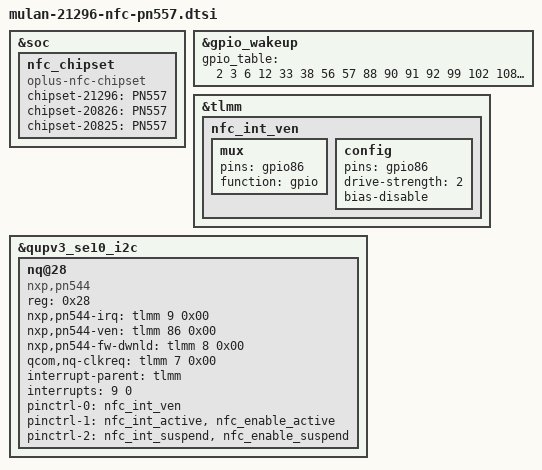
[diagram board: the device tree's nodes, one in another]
/**********************************************************************************
* Copyright (c)  2008-2020  Guangdong oplus Mobile Comm Corp., Ltd
* VENDOR_EDIT
* Description: oplus pn557 nfc dtsi
*
* Version: 1.0
* Date: 2020-09-16
* Author: Weiwei.Deng
*
* ------------------------------ Revision History: --------------------------------
* <version>           <date>                <author>                            <desc>
* Revision 1.0       2020-11-16            wenjie.liu           Created for Beta pn557 nfc dtsi
***********************************************************************************/
&soc {
	//add for nfc_chipset
	nfc_chipset {
        compatible = "oplus-nfc-chipset";
	chipset-21296 = "PN557";
        chipset-20826 = "PN557";
        chipset-20825 = "PN557";
	};
};

//add for disable wake-up function of NC-GPIO
&gpio_wakeup {
    gpio_table = <2 3 6 12 33 38 56 57 88 90 91 92 99 102 108 113 114 115 116
                  48 51 59 84 85 107 117 118 152 153 154 155>;
};

&tlmm {
    nfc_int_ven: nfc_int_ven {
	mux {
		pins = "gpio86";
		function = "gpio";
	};

	config {
		pins = "gpio86";
		drive-strength = <2>; /* 2 MA */
		bias-disable;
	};
    };
};


&qupv3_se10_i2c {
    //add for NXP PN557 NFC GPIO
	status = "ok";
	//qcom,clk-freq-out = <1000000>;
	#address-cells = <1>;
	#size-cells = <0>;
	nq@28 {
		compatible = "nxp,pn544";
		reg = <0x28>;
		nxp,pn544-irq = <&tlmm 9 0x00>;
		nxp,pn544-ven = <&tlmm 86 0x00>;
		nxp,pn544-fw-dwnld = <&tlmm 8 0x00>;
		qcom,nq-clkreq = <&tlmm 7 0x00>;
		interrupt-parent = <&tlmm>;
		interrupts = <9 0>;
		interrupt-names = "nfc_irq";
		pinctrl-names = "default","nfc_active", "nfc_suspend";
		pinctrl-0 = <&nfc_int_ven>;
		pinctrl-1 = <&nfc_int_active &nfc_enable_active>;
		pinctrl-2 = <&nfc_int_suspend &nfc_enable_suspend>;
	};
};
